# system_timer_octs: IP-XACT component
VLNV tenstorrent.com:ocah:system_timer_octs:1.0

## Address spaces and blocks
system_timer_octs_mmap.system_timer_octs: base 'h0, range 'h24, width 32

## Registers
Registers are 32-bit, read-write, reset 0x0 unless marked. A register's access mark holds for its fields unless they carry their own. Offsets are from the block's base; lines under a group give offsets from that group; [hi:lo] are bit positions; {n}, {i} and the like mark numbered series; 'fields as' and 'values as' point back to an identical list; <NAME> marks a mode.

## system_timer_octs_mmap.system_timer_octs — Open Chiplet Time Synchronization (OCTS) System Timer Registers
Base 0x00000000
0x00 TIMER_START — System Timer Start Register
  [0] START — Start the system timer. In PRIMARY mode, a write of 1 loads the preset and pulses the sync-load output for PULSE_WIDTH cycles. In SECONDARY mode, the write has no effect; a secondary starts on the primary's sync-load pulse, which is what loads its preset. Ensure both primary and secondary are out of reset.
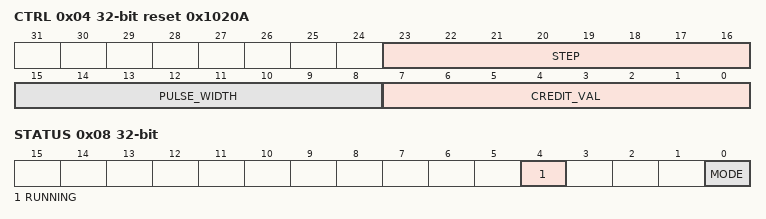
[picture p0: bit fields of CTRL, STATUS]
0x04 CTRL reset 0x1020A — System Timer Control Register
  [23:16] STEP — Step amount for secondary timer
  [15:8] PULSE_WIDTH — Pulse width for sync load and credit signals. A value of 0 will be rounded up to 1. WARNING: This value must be less than CREDIT_VAL
  [7:0] CREDIT_VAL — Credit value factor. WARNING: This value must be greater than PULSE_WIDTH
0x08 STATUS ro — System Timer Status Register
  [4] RUNNING — Timer is enabled and its count is nonzero.
  [0] MODE — Timer mode driven by the is_primary_i input: 0=PRIMARY (is_primary_i=1), 1=SECONDARY (is_primary_i=0).
0x0C TIMER_PRESET_LO — System Timer Preset Value [31:0]
  [31:0] PRESET_LO — Lower 32 bits of preset value
0x10 TIMER_PRESET_HI — System Timer Preset Value [63:32]
  [31:0] PRESET_HI — Upper 32 bits of preset value
0x14 TIMER_COUNT_LO ro — Current System Timer Count [31:0]
  [31:0] COUNT_LO — Lower 32 bits of current timer count
0x18 TIMER_COUNT_HI ro — Current System Timer Count [63:32]
  [31:0] COUNT_HI — Upper 32 bits of current timer count
0x1C CREDIT_EXPIRED
  [31:0] MAX_CYCLES_EXPIRED — Maximum number of clock cycles since a count credit expired (SECONDARY only). To reset the value of this register, write anything to it. If this number is very high (exact value depends on clock speed and credit value), this indicates that the secondary has not received a count credit pulse in a while, and is likely not syncing properly with the primary. This register can also be used to determine the clock skew between the primary and secondary. If PRIMARY, this field is always 0.
0x20 TIMER_GPIO_ENABLE — System Timer GPIO Enable Register
  [0] GPIO_ENABLE — Enable the GPIO pad lsio interface for the system timer. This is done to prevent X-prop on reset into the secondary timer, which can cause the secondary timer to start counting early.

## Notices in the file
SPDX-License-Identifier: Apache-2.0
SPDX-FileCopyrightText: 2026 Tenstorrent USA, Inc.
